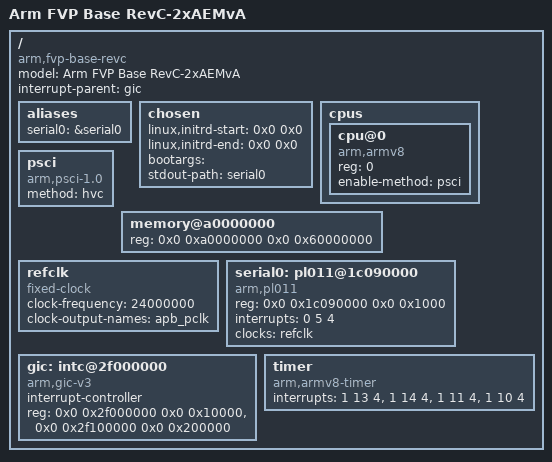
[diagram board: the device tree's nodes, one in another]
/dts-v1/;

/ {
    compatible = "arm,fvp-base-revc";
    model = "Arm FVP Base RevC-2xAEMvA";
    #address-cells = <2>;
    #size-cells = <2>;
    interrupt-parent = <&gic>;

    aliases {
        serial0 = &serial0;
    };

    chosen {
        linux,initrd-start = <0x0 0x0>;
        linux,initrd-end = <0x0 0x0>;
        bootargs = "";
        stdout-path = "serial0";
    };

    cpus {
        #address-cells = <1>;
        #size-cells = <0>;

        cpu@0 {
            device_type = "cpu";
            compatible = "arm,armv8";
            reg = <0>;
            enable-method = "psci";
        };
    };

    psci {
        compatible = "arm,psci-1.0";
        method = "hvc";
    };

    memory@a0000000 {
        device_type = "memory";
        reg = <0x0 0xa0000000 0x0 0x60000000>;
    };

    refclk: refclk {
        compatible = "fixed-clock";
        #clock-cells = <0>;
        clock-frequency = <24000000>;
        clock-output-names = "apb_pclk";
    };

    serial0: pl011@1c090000 {
        compatible = "arm,pl011", "arm,primecell";
        reg = <0x0 0x1c090000 0x0 0x1000>;
        interrupts = <0 5 4>;
        clocks = <&refclk>;
        clock-names = "apb_pclk";
    };

    gic: intc@2f000000 {
        compatible = "arm,gic-v3";
        #interrupt-cells = <3>;
        interrupt-controller;
        reg = <0x0 0x2f000000 0x0 0x10000>,
              <0x0 0x2f100000 0x0 0x200000>;
    };

    timer {
        compatible = "arm,armv8-timer";
        interrupts = <1 13 4>, <1 14 4>, <1 11 4>, <1 10 4>;
    };
};
